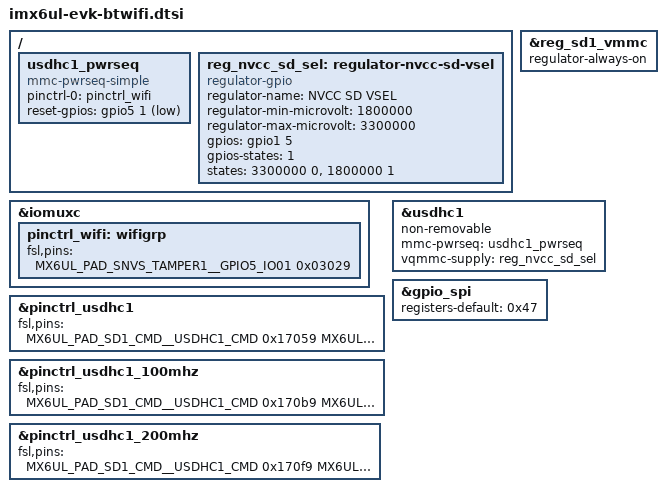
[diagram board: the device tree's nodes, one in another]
// SPDX-License-Identifier: (GPL-2.0+ OR MIT)
/*
 * Copyright 2021-2023 NXP
 */

/*
 * NOTE: This DTS file is written for the wifi chips that supporting 1.8V
 * SDIO3.0, and also 3.3V SDIO2.0
 */


/ {
	usdhc1_pwrseq: usdhc1_pwrseq {
		pinctrl-names = "default";
		pinctrl-0 = <&pinctrl_wifi>;
		compatible = "mmc-pwrseq-simple";
		reset-gpios = <&gpio5 1 GPIO_ACTIVE_LOW>;
	};


	reg_nvcc_sd_sel: regulator-nvcc-sd-vsel {
		compatible = "regulator-gpio";
		regulator-name = "NVCC SD VSEL";
		regulator-min-microvolt = <1800000>;
		regulator-max-microvolt = <3300000>;
		gpios = <&gpio1 5 GPIO_ACTIVE_HIGH>;
		gpios-states = <1>;
		states = <3300000 0>, <1800000 1>;
	};
};

&iomuxc {
	pinctrl_wifi: wifigrp {
		fsl,pins = <
			MX6UL_PAD_SNVS_TAMPER1__GPIO5_IO01 0x03029
		>;
	};
};

&pinctrl_usdhc1 {
	fsl,pins = <
		MX6UL_PAD_SD1_CMD__USDHC1_CMD		0x17059
		MX6UL_PAD_SD1_CLK__USDHC1_CLK		0x10071
		MX6UL_PAD_SD1_DATA0__USDHC1_DATA0	0x17059
		MX6UL_PAD_SD1_DATA1__USDHC1_DATA1	0x17059
		MX6UL_PAD_SD1_DATA2__USDHC1_DATA2	0x17059
		MX6UL_PAD_SD1_DATA3__USDHC1_DATA3	0x17059
		MX6UL_PAD_GPIO1_IO05__GPIO1_IO05	0x17059 /* SD1 VSELECT */
		MX6UL_PAD_GPIO1_IO09__GPIO1_IO09	0x17059 /* SD1 RESET */
	>;
};

&pinctrl_usdhc1_100mhz {
		fsl,pins = <
		MX6UL_PAD_SD1_CMD__USDHC1_CMD		0x170b9
		MX6UL_PAD_SD1_CLK__USDHC1_CLK		0x100b9
		MX6UL_PAD_SD1_DATA0__USDHC1_DATA0	0x170b9
		MX6UL_PAD_SD1_DATA1__USDHC1_DATA1	0x170b9
		MX6UL_PAD_SD1_DATA2__USDHC1_DATA2	0x170b9
		MX6UL_PAD_SD1_DATA3__USDHC1_DATA3	0x170b9
		MX6UL_PAD_GPIO1_IO05__GPIO1_IO05	0x170b9 /* SD1 VSELECT */
		MX6UL_PAD_GPIO1_IO09__GPIO1_IO09	0x170b9 /* SD1 RESET */
	>;
};

&pinctrl_usdhc1_200mhz {
		fsl,pins = <
		MX6UL_PAD_SD1_CMD__USDHC1_CMD		0x170f9
		MX6UL_PAD_SD1_CLK__USDHC1_CLK		0x100f9
		MX6UL_PAD_SD1_DATA0__USDHC1_DATA0	0x170f9
		MX6UL_PAD_SD1_DATA1__USDHC1_DATA1	0x170f9
		MX6UL_PAD_SD1_DATA2__USDHC1_DATA2	0x170f9
		MX6UL_PAD_SD1_DATA3__USDHC1_DATA3	0x170f9
		MX6UL_PAD_GPIO1_IO05__GPIO1_IO05	0x170f9 /* SD1 VSELECT */
		MX6UL_PAD_GPIO1_IO09__GPIO1_IO09	0x170f9 /* SD1 RESET */
	>;
};

&reg_sd1_vmmc {
	regulator-always-on;
};

&usdhc1 {
	#address-cells = <1>;
	#size-cells = <0>;
	non-removable;
	mmc-pwrseq = <&usdhc1_pwrseq>;

	/* Here config the vsel pad as an normal gpio, and use
	 * the vqmmc(gpio-regulator) method to do the IO voltage switch.
	 * set gpio to low level select 3.3v, and high level select 1.8v
	 * If not, when config this pin as vsel specific function,
	 * though work normal when sdio boot up and in SDIO 3.0 mode,
	 * but will meet issue after system resume back from mem
	 * mode, because after system suspend in mem mode, usdhc
	 * will lost power, so when resume back, all register
	 * return to default state, need driver to re-config.
	 * But for sdio wifi device, we config this device with
	 * flag keep-power-in-suspend, so sdio wifi do nothing
	 * during system PM, only mark re-tuning flag. When
	 * system resume back, the original vsel bit lost, which
	 * means the IO voltage change to 3.3v, but sdio wifi still
	 * in SDIO3.0 mode, expect the IO voltage in 1.8v, IO
	 * voltage mismatch happened, data transfer in this time
	 * will meet CRC/Timeout issue.
	 */
	vqmmc-supply = <&reg_nvcc_sd_sel>;
	/delete-property/ enable-sdio-wakeup;
	/delete-property/ cd-gpios;
};

&gpio_spi {
	/* Murata: modify default setting so that BT_nPWD/BT_REG_ON
	 * is low (0V) during kernel boot.
	 */
	registers-default = /bits/ 8 <0x47>;
};
